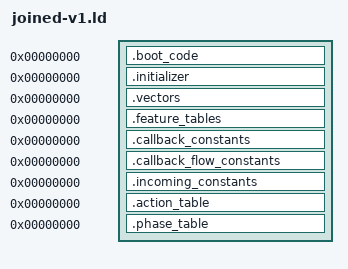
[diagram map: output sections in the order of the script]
OUTPUT_ARCH(riscv)
SECTIONS
{
 .boot_code 0 : SUBALIGN(2) { *(.boot_code)
  *(.text.tsl9_record_dispatch_provider_a6aa)
  *(.text.tsl9_record_helpers_block_a6b4)
  *(.text.tsl9_record_helpers_block_a6cc)
  *(.text.tsl9_record_helpers_block_a6d6)
  *(.text.tsl9_record_dispatch_provider_b0b0)
  *(.text.tsl9_record_dispatch_provider_b572)
  *(.text.tsl9_record_dispatch_provider_b594)
  *(.text.tsl9_record_helpers_block_b59c)
  *(.text.tsl9_record_helpers_block_b59e)
  *(.text.tsl9_record_helpers_block_b5aa)
  *(.text.tsl9_record_actions_provider_de82)
  *(.text.tsl9_record_helpers_block_de8e)
  *(.text.tsl9_record_helpers_block_de9e)
  *(.text.tsl9_record_dispatch_provider_ef76)
  *(.text.tsl9_record_helpers_block_ef82)
  *(.text.tsl9_record_helpers_block_ef84)
  *(.text.tsl9_record_helpers_block_ef8a)
  *(.text.tsl9_record_helpers_block_efa0)
  *(.text.tsl9_record_helpers_block_efa6)
  *(.text.tsl9_record_helpers_block_efac)
  *(.text.tsl9_record_helpers_block_efb4)
  *(.text.tsl9_record_helpers_block_efbe)
  *(.text.tsl9_record_helpers_block_efee)
  *(.text.tsl9_record_helpers_block_eff8)
  *(.text.tsl9_record_helpers_block_f00e)
  *(.text.tsl9_record_dispatch_provider_f016)
  *(.text.tsl9_record_helpers_block_f030)
  *(.text.tsl9_record_helpers_block_f038)
  *(.text.tsl9_record_actions_provider_f058)
  *(.text.tsl9_record_helpers_block_f05a)
  *(.text.tsl9_record_helpers_block_f06e)
  *(.text.tsl9_record_helpers_block_f078)
  *(.text.tsl9_record_helpers_block_f07c)
  *(.text.tsl9_record_helpers_block_f08c)
  *(.text.tsl9_record_helpers_block_f09c)
  *(.text.tsl9_record_actions_provider_f47e)
  *(.text.tsl9_record_helpers_block_f490)
  *(.text.tsl9_record_helpers_block_f492)
  *(.text.tsl9_record_helpers_block_f49a)
  *(.text.tsl9_record_helpers_block_f49c)
  *(.text.tsl9_record_helpers_block_f4a2)
  *(.text.tsl9_record_helpers_block_f4b0)
  *(.text.tsl9_record_helpers_block_f4c2)
  *(.text.tsl9_record_helpers_block_f4c8)
  *(.text.tsl9_record_helpers_block_f4ce)
  *(.text.tsl9_record_actions_provider_f4d0)
  *(.text.tsl9_record_helpers_block_f4de)
  *(.text.tsl9_record_helpers_block_f506)
  *(.text.tsl9_record_helpers_block_f518)
  *(.text.tsl9_record_helpers_block_f52e)
  *(.text.tsl9_record_helpers_block_f546)
  *(.text.tsl9_record_helpers_block_f55c)
  *(.text.tsl9_record_helpers_block_f572)
  *(.text.tsl9_record_actions_provider_f578)
  *(.text.tsl9_record_helpers_block_f588)
  *(.text.tsl9_record_helpers_block_f5aa)
  *(.text.tsl9_record_helpers_block_f5b0)
  *(.text.tsl9_record_helpers_block_f5be)
  *(.text.tsl9_record_helpers_block_f5c8)
  *(.text.tsl9_record_helpers_block_f5d8)
  *(.text.tsl9_record_helpers_block_f5f0)
  *(.text.tsl9_record_helpers_block_f602)
  *(.text.tsl9_record_helpers_block_f618)
  *(.text.tsl9_record_helpers_block_f620)
  *(.text.tsl9_record_dispatch_provider_18218)
  *(.text.tsl9_record_helpers_block_18228)
  *(.text.tsl9_record_helpers_block_1822a)
  *(.text.tsl9_record_helpers_block_1822e)
 }
 .initializer 0 : SUBALIGN(4) { *(.initializer) }
 .vectors 0 : SUBALIGN(4) { *(.vectors) }
 .feature_tables 0 : SUBALIGN(4) { *(.feature_tables) }
 .callback_constants 0 : SUBALIGN(4) { *(.callback_constants) }
 .callback_flow_constants 0 : SUBALIGN(4) { *(.callback_flow_constants) }
 .incoming_constants 0 : SUBALIGN(4) { *(.incoming_constants) }
 .action_table 0 : SUBALIGN(4) { *(.action_table) }
 .phase_table 0 : SUBALIGN(4) { *(.phase_table) }
 /DISCARD/ : { *(.comment) *(.riscv.attributes) *(.llvm_addrsig) }
}
